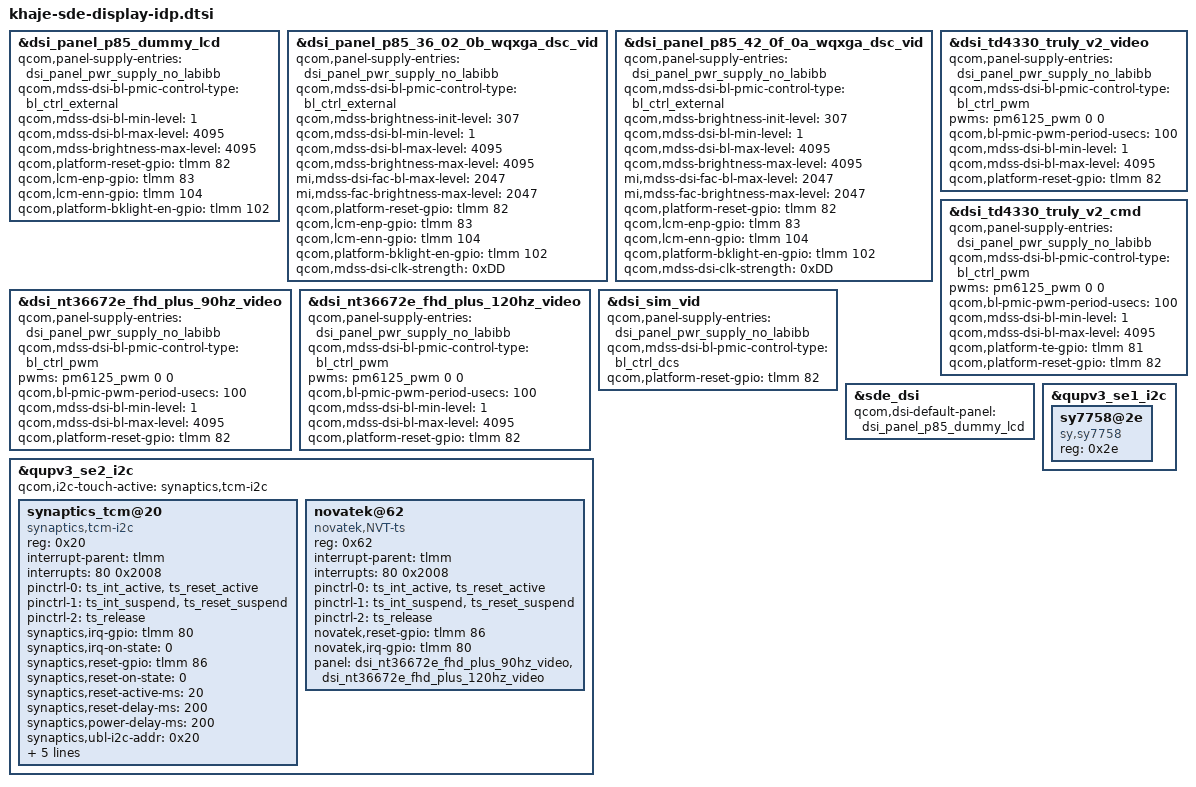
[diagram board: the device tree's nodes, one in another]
#include "touchscreen.dtsi"
#include "khaje-sde-display.dtsi"
&dsi_panel_p85_dummy_lcd {
	qcom,panel-supply-entries = <&dsi_panel_pwr_supply_no_labibb>;
	qcom,mdss-dsi-bl-pmic-control-type = "bl_ctrl_external";
	qcom,mdss-dsi-bl-min-level = <1>;
	qcom,mdss-dsi-bl-max-level = <4095>;
        qcom,mdss-brightness-max-level = <4095>;
	qcom,platform-reset-gpio = <&tlmm 82 0>;
	qcom,lcm-enp-gpio = <&tlmm 83 0>;
	qcom,lcm-enn-gpio = <&tlmm 104 0>;
	qcom,platform-bklight-en-gpio = <&tlmm 102 0>;
};

&dsi_panel_p85_36_02_0b_wqxga_dsc_vid {
	qcom,panel-supply-entries = <&dsi_panel_pwr_supply_no_labibb>;
	qcom,mdss-dsi-bl-pmic-control-type = "bl_ctrl_external";
	qcom,mdss-brightness-init-level = <307>;
	qcom,mdss-dsi-bl-min-level = <1>;
	qcom,mdss-dsi-bl-max-level = <4095>;
        qcom,mdss-brightness-max-level = <4095>;
        mi,mdss-dsi-fac-bl-max-level = <2047>;
        mi,mdss-fac-brightness-max-level = <2047>;
	qcom,platform-reset-gpio = <&tlmm 82 0>;
	qcom,lcm-enp-gpio = <&tlmm 83 0>;
	qcom,lcm-enn-gpio = <&tlmm 104 0>;
	qcom,platform-bklight-en-gpio = <&tlmm 102 0>;
	qcom,mdss-dsi-clk-strength = <0xDD>;
};

&dsi_panel_p85_42_0f_0a_wqxga_dsc_vid {
	qcom,panel-supply-entries = <&dsi_panel_pwr_supply_no_labibb>;
	qcom,mdss-dsi-bl-pmic-control-type = "bl_ctrl_external";
	qcom,mdss-brightness-init-level = <307>;
	qcom,mdss-dsi-bl-min-level = <1>;
	qcom,mdss-dsi-bl-max-level = <4095>;
	qcom,mdss-brightness-max-level = <4095>;
	mi,mdss-dsi-fac-bl-max-level = <2047>;
	mi,mdss-fac-brightness-max-level = <2047>;
	qcom,platform-reset-gpio = <&tlmm 82 0>;
	qcom,lcm-enp-gpio = <&tlmm 83 0>;
	qcom,lcm-enn-gpio = <&tlmm 104 0>;
	qcom,platform-bklight-en-gpio = <&tlmm 102 0>;
	qcom,mdss-dsi-clk-strength = <0xDD>;
};

&dsi_td4330_truly_v2_video {
	qcom,panel-supply-entries = <&dsi_panel_pwr_supply_no_labibb>;
	qcom,mdss-dsi-bl-pmic-control-type = "bl_ctrl_pwm";
	pwms = <&pm6125_pwm 0 0>;
	qcom,bl-pmic-pwm-period-usecs = <100>;
	qcom,mdss-dsi-bl-min-level = <1>;
	qcom,mdss-dsi-bl-max-level = <4095>;
	qcom,platform-reset-gpio = <&tlmm 82 0>;
};

&dsi_td4330_truly_v2_cmd {
	qcom,panel-supply-entries = <&dsi_panel_pwr_supply_no_labibb>;
	qcom,mdss-dsi-bl-pmic-control-type = "bl_ctrl_pwm";
	pwms = <&pm6125_pwm 0 0>;
	qcom,bl-pmic-pwm-period-usecs = <100>;
	qcom,mdss-dsi-bl-min-level = <1>;
	qcom,mdss-dsi-bl-max-level = <4095>;
	qcom,platform-te-gpio = <&tlmm 81 0>;
	qcom,platform-reset-gpio = <&tlmm 82 0>;
};

&dsi_nt36672e_fhd_plus_90hz_video {
	qcom,panel-supply-entries = <&dsi_panel_pwr_supply_no_labibb>;
	qcom,mdss-dsi-bl-pmic-control-type = "bl_ctrl_pwm";
	pwms = <&pm6125_pwm 0 0>;
	qcom,bl-pmic-pwm-period-usecs = <100>;
	qcom,mdss-dsi-bl-min-level = <1>;
	qcom,mdss-dsi-bl-max-level = <4095>;
	qcom,platform-reset-gpio = <&tlmm 82 0>;
};

&dsi_nt36672e_fhd_plus_120hz_video {
	qcom,panel-supply-entries = <&dsi_panel_pwr_supply_no_labibb>;
	qcom,mdss-dsi-bl-pmic-control-type = "bl_ctrl_pwm";
	pwms = <&pm6125_pwm 0 0>;
	qcom,bl-pmic-pwm-period-usecs = <100>;
	qcom,mdss-dsi-bl-min-level = <1>;
	qcom,mdss-dsi-bl-max-level = <4095>;
	qcom,platform-reset-gpio = <&tlmm 82 0>;
};

&dsi_sim_vid {
	qcom,panel-supply-entries = <&dsi_panel_pwr_supply_no_labibb>;
	qcom,mdss-dsi-bl-pmic-control-type = "bl_ctrl_dcs";
	qcom,platform-reset-gpio = <&tlmm 82 0>;
};

&sde_dsi {
	qcom,dsi-default-panel = <&dsi_panel_p85_dummy_lcd>;
};

&qupv3_se1_i2c {
	status = "okay";
	sy7758@2e {
		compatible = "sy,sy7758";
		reg = <0x2e>;
	};
};

&qupv3_se2_i2c {
	status = "okay";
	qcom,i2c-touch-active="synaptics,tcm-i2c";

	synaptics_tcm@20 {
		compatible = "synaptics,tcm-i2c";
		reg = <0x20>;
		interrupt-parent = <&tlmm>;
		interrupts = <80 0x2008>;
		pinctrl-names = "pmx_ts_active","pmx_ts_suspend",
			"pmx_ts_release";
		pinctrl-0 = <&ts_int_active &ts_reset_active>;
		pinctrl-1 = <&ts_int_suspend &ts_reset_suspend>;
		pinctrl-2 = <&ts_release>;
		synaptics,irq-gpio = <&tlmm 80 0x2008>;
		synaptics,irq-on-state = <0>;
		synaptics,reset-gpio = <&tlmm 86 0x00>;
		synaptics,reset-on-state = <0>;
		synaptics,reset-active-ms = <20>;
		synaptics,reset-delay-ms = <200>;
		synaptics,power-delay-ms = <200>;
		synaptics,ubl-i2c-addr = <0x20>;
		synaptics,extend_report;
		synaptics,firmware-name = "synaptics_firmware_k.img";

		panel = <&dsi_td4330_truly_v2_video &dsi_td4330_truly_v2_cmd>;
	};

	novatek@62 {
		compatible = "novatek,NVT-ts";
		reg = <0x62>;
		status = "ok";

		interrupt-parent = <&tlmm>;
		interrupts = <80 0x2008>;
		pinctrl-names = "pmx_ts_active","pmx_ts_suspend",
			"pmx_ts_release";
		pinctrl-0 = <&ts_int_active &ts_reset_active>;
		pinctrl-1 = <&ts_int_suspend &ts_reset_suspend>;
		pinctrl-2 = <&ts_release>;

		novatek,reset-gpio = <&tlmm 86 0x00>;
		novatek,irq-gpio = <&tlmm 80 0x2008>;

		panel = <&dsi_nt36672e_fhd_plus_90hz_video
			&dsi_nt36672e_fhd_plus_120hz_video>;
	};
};
